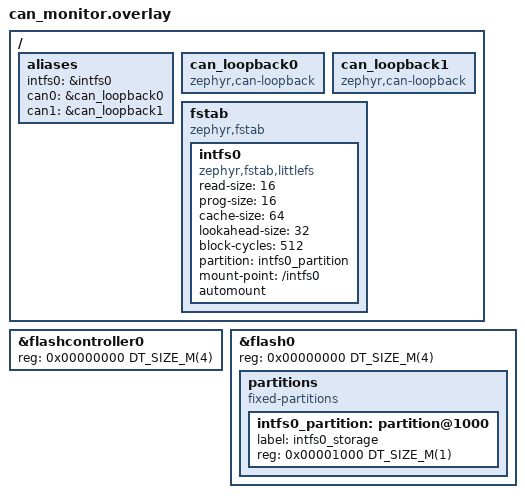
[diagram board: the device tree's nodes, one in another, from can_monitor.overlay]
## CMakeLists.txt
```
cmake_minimum_required(VERSION 3.20.0)

# The scenario that compiles the CAN monitor's controller (lint.bluetooth.can_monitor) passes this.
if(RT_CORE_LINT_CAN_MONITOR)
    list(APPEND EXTRA_DTC_OVERLAY_FILE "${CMAKE_CURRENT_SOURCE_DIR}/can_monitor.overlay")
endif()

include(${CMAKE_CURRENT_SOURCE_DIR}/../../rt_core_test.cmake)

find_package(Zephyr REQUIRED HINTS $ENV{ZEPHYR_BASE})
project(lint_bluetooth)

target_sources(app PRIVATE src/main.cpp)
```

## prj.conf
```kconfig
# This scenario only exists so that clang-tidy sees the Bluetooth stack (plan D7): the native_sim
# compile database it produces contains ble.cpp, access_point_service.cpp, ble_service.cpp and
# ble_controller.cpp, which no other native_sim suite builds. It is build only and never run.

# Language and Compiler
CONFIG_CPP=y
CONFIG_STD_CPP23=y
CONFIG_REQUIRES_FULL_LIBCPP=y
CONFIG_CPP_EXCEPTIONS=y
CONFIG_CPP_RTTI=y

# Memory (the Bluetooth stack allocates from the kernel heap)
CONFIG_HEAP_MEM_POOL_SIZE=65536

# Logging And Debugging
CONFIG_LOG=y
CONFIG_THREAD_NAME=y

# Bluetooth (native_sim's devicetree already selects the HCI user channel driver)
CONFIG_BT=y
CONFIG_BT_PERIPHERAL=y
# ble.cpp asserts a single connection
CONFIG_BT_MAX_CONN=1
# ble.cpp sets bt_conn_cb.security_changed
CONFIG_BT_SMP=y
CONFIG_BT_USER_PHY_UPDATE=y
CONFIG_BT_USER_DATA_LEN_UPDATE=y

# The BLE domain reads sensors and the system state, which pull in the rest of this list
CONFIG_ADC=y
CONFIG_CAN=y
CONFIG_ZCBOR=y

CONFIG_EERIE_LEAP_RT_CORE=y
CONFIG_EERIE_LEAP_THREADING=y
CONFIG_EERIE_LEAP_CONFIGURATION=y
CONFIG_EERIE_LEAP_ADC=y
CONFIG_EERIE_LEAP_CANBUS=y
CONFIG_EERIE_LEAP_EXPRESSION_ENGINE=y
CONFIG_EERIE_LEAP_LUA_SCRIPT=y
CONFIG_EERIE_LEAP_BLUETOOTH=y
CONFIG_EERIE_LEAP_DOMAIN_SENSOR=y
CONFIG_EERIE_LEAP_DOMAIN_SYSTEM=y
CONFIG_EERIE_LEAP_DOMAIN_BLE=y
CONFIG_EERIE_LEAP_CONTROLLER_BLE=y
```

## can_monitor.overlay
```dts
/* The second scenario (lint.bluetooth.can_monitor): the devicetree the CAN bus controller needs, with the
 * internal filesystem and two CAN ports. */
/ {
	aliases {
		intfs0 = &intfs0;
		can0 = &can_loopback0;
		can1 = &can_loopback1;
	};

	can_loopback0: can_loopback0 {
		status = "okay";
		compatible = "zephyr,can-loopback";
	};

	can_loopback1: can_loopback1 {
		status = "okay";
		compatible = "zephyr,can-loopback";
	};

	fstab {
		compatible = "zephyr,fstab";
		intfs0: intfs0 {
			compatible = "zephyr,fstab,littlefs";
			read-size = <16>;
			prog-size = <16>;
			cache-size = <64>;
			lookahead-size = <32>;
			block-cycles = <512>;
			partition = <&intfs0_partition>;
			mount-point = "/intfs0";
			automount;
		};
	};
};

&flashcontroller0 {
	reg = <0x00000000 DT_SIZE_M(4)>;
};

&flash0 {
	reg = <0x00000000 DT_SIZE_M(4)>;

	partitions {
		compatible = "fixed-partitions";
		#address-cells = <1>;
		#size-cells = <1>;

		intfs0_partition: partition@1000 {
			label = "intfs0_storage";
			reg = <0x00001000 DT_SIZE_M(1)>;
		};
	};
};
```

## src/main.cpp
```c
// Build-only scenario: see prj.conf. The Bluetooth stack sources are compiled through Kconfig,
// so nothing has to be referenced from here.
int main() {
    return 0;
}
```
